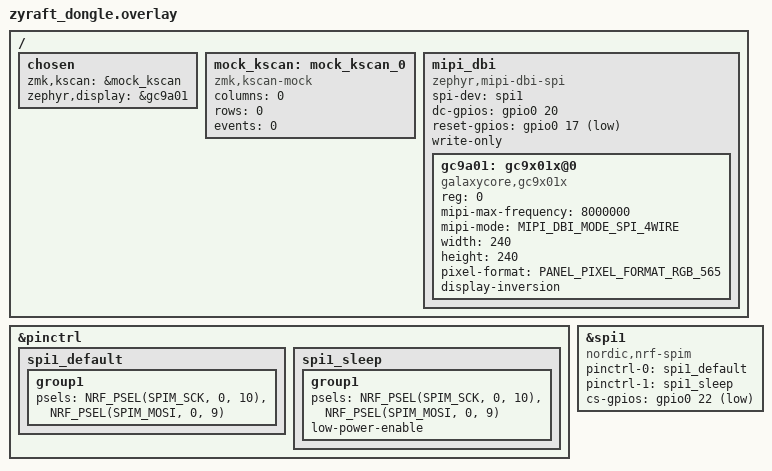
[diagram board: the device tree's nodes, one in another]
/*
 * Zyra FT dongle shield z wyświetlaczem GC9A01 240x240 round
 *
 * Pinout:
 *  GC9A01 SCL  -> P0.10
 *  GC9A01 SDA  -> P0.09
 *  GC9A01 RES  -> P0.17
 *  GC9A01 DC   -> P0.20
 *  GC9A01 CS   -> P0.22
 *  GC9A01 BL   -> P0.24
 *  GC9A01 VCC  -> 3V3
 *  GC9A01 GND  -> GND
 */

#include <zephyr/dt-bindings/display/panel.h>
#include "zyraft-layouts.dtsi"

&pinctrl {
    spi1_default: spi1_default {
        group1 {
            psels = <NRF_PSEL(SPIM_SCK, 0, 10)>,
                    <NRF_PSEL(SPIM_MOSI, 0, 9)>;
        };
    };

    spi1_sleep: spi1_sleep {
        group1 {
            psels = <NRF_PSEL(SPIM_SCK, 0, 10)>,
                    <NRF_PSEL(SPIM_MOSI, 0, 9)>;
            low-power-enable;
        };
    };
};

&spi1 {
    compatible = "nordic,nrf-spim";
    status = "okay";

    pinctrl-0 = <&spi1_default>;
    pinctrl-1 = <&spi1_sleep>;
    pinctrl-names = "default", "sleep";

    cs-gpios = <&gpio0 22 GPIO_ACTIVE_LOW>;
};

/ {
    chosen {
        zmk,kscan = &mock_kscan;
        zephyr,display = &gc9a01;
    };

    mock_kscan: mock_kscan_0 {
        compatible = "zmk,kscan-mock";
        columns = <0>;
        rows = <0>;
        events = <0>;
    };

    /*
     * Backlight najlepiej na start podłącz fizycznie:
     * BL -> 3V3
     *
     * PWM na P0.24 usuwamy na razie, żeby nie blokował startu ekranu.
     * Jak ekran ruszy, potem dodamy sterowanie jasnością.
     */

    mipi_dbi {
        compatible = "zephyr,mipi-dbi-spi";
        spi-dev = <&spi1>;

        dc-gpios = <&gpio0 20 GPIO_ACTIVE_HIGH>;
        reset-gpios = <&gpio0 17 GPIO_ACTIVE_LOW>;

        write-only;

        #address-cells = <1>;
        #size-cells = <0>;

        gc9a01: gc9x01x@0 {
            compatible = "galaxycore,gc9x01x";
            reg = <0>;

            mipi-max-frequency = <8000000>;
            mipi-mode = "MIPI_DBI_MODE_SPI_4WIRE";

            width = <240>;
            height = <240>;
            pixel-format = <PANEL_PIXEL_FORMAT_RGB_565>;

            display-inversion;
        };
    };
};
